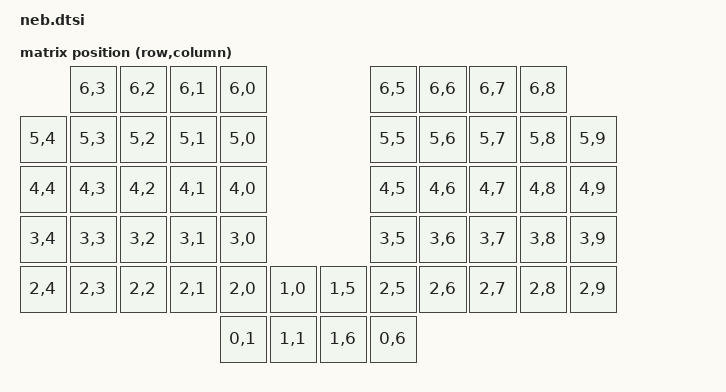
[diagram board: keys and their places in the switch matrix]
// This file was generated from a template. Edit it to match your keyboard.
// See https://zmk.dev/docs/development/hardware-integration/new-shield for more
// instructions.

#include <dt-bindings/zmk/matrix_transform.h>

#include "neb-layouts.dtsi"

/ {
    chosen {
        zmk,physical-layout = &default_layout;
    };

    kscan: kscan {
        compatible = "zmk,kscan-gpio-matrix";
        diode-direction = "col2row";
        wakeup-source;
    };

    default_transform: default_transform {
        // See https://zmk.dev/docs/development/hardware-integration/new-shield#matrix-transform
        // for how to configure this
		compatible = "zmk,matrix-transform";
		columns = <10>;
		rows = <7>;

		map = <
                                   // Left Half                     // Right Half
                RC(6,3) RC(6,2) RC(6,1) RC(6,0)                     RC(6,5) RC(6,6) RC(6,7) RC(6,8)
        RC(5,4) RC(5,3) RC(5,2) RC(5,1) RC(5,0)                     RC(5,5) RC(5,6) RC(5,7) RC(5,8) RC(5,9)
        RC(4,4) RC(4,3) RC(4,2) RC(4,1) RC(4,0)                     RC(4,5) RC(4,6) RC(4,7) RC(4,8) RC(4,9)
        RC(3,4) RC(3,3) RC(3,2) RC(3,1) RC(3,0)                     RC(3,5) RC(3,6) RC(3,7) RC(3,8) RC(3,9)
        RC(2,4) RC(2,3) RC(2,2) RC(2,1) RC(2,0) RC(1,0)     RC(1,5) RC(2,5) RC(2,6) RC(2,7) RC(2,8) RC(2,9)
                                        RC(0,1) RC(1,1)     RC(1,6) RC(0,6)		
        >;					
    };
};
